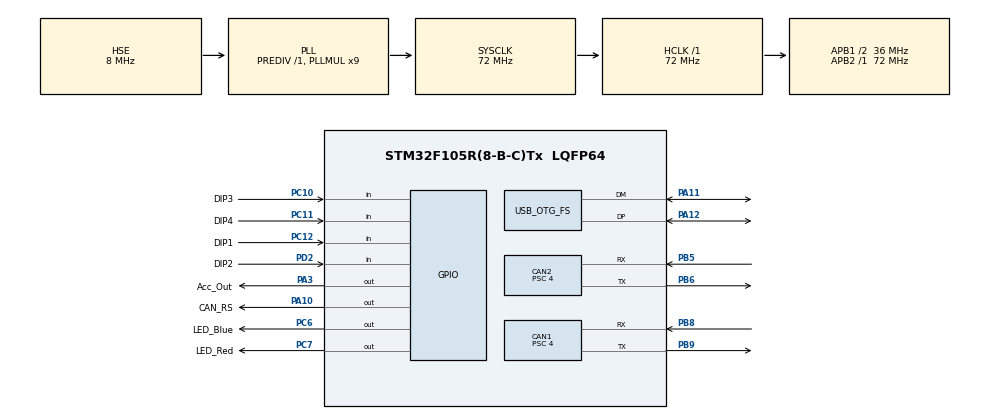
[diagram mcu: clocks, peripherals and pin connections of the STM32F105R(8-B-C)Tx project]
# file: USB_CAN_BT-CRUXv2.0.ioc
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CAN1.ABOM=ENABLE
CAN1.AWUM=ENABLE
CAN1.BS1=CAN_BS1_15TQ
CAN1.BS2=CAN_BS2_2TQ
CAN1.CalculateTimeBit=2000
CAN1.CalculateTimeQuantum=111.11111111111111
CAN1.NART=ENABLE
CAN1.Prescaler=4
CAN1.TXFP=ENABLE
CAN2.ABOM=ENABLE
CAN2.AWUM=ENABLE
CAN2.BS1=CAN_BS1_15TQ
CAN2.BS2=CAN_BS2_2TQ
CAN2.CalculateTimeBit=2000
CAN2.CalculateTimeQuantum=111.11111111111111
CAN2.NART=ENABLE
CAN2.Prescaler=4
CAN2.TXFP=ENABLE
Mcu.Family=STM32F1
Mcu.Name=STM32F105R(8-B-C)Tx
Mcu.Package=LQFP64
NVIC.CAN1_RX0_IRQn=true\:3\:0\:true\:false\:true\:true\:true
NVIC.CAN2_RX0_IRQn=true\:3\:0\:true\:false\:true\:true\:true
NVIC.OTG_FS_IRQn=true\:7\:0\:true\:false\:true\:false\:true
NVIC.PriorityGroup=NVIC_PRIORITYGROUP_4
PA10.GPIO_Label=CAN_RS
PA10.Signal=GPIO_Output
PA11.Mode=Device_Only
PA11.Signal=USB_OTG_FS_DM
PA12.Mode=Device_Only
PA12.Signal=USB_OTG_FS_DP
PA13.Mode=Serial_Wire
PA13.Signal=SYS_JTMS-SWDIO
PA14.Mode=Serial_Wire
PA14.Signal=SYS_JTCK-SWCLK
PA3.GPIO_Label=Acc_Out
PA3.Signal=GPIO_Output
PB5.Mode=Slave
PB5.Signal=CAN2_RX
PB6.Mode=Slave
PB6.Signal=CAN2_TX
PB8.GPIO_PuPd=GPIO_NOPULL
PB8.Mode=Master
PB8.Signal=CAN1_RX
PB9.Mode=Master
PB9.Signal=CAN1_TX
PC10.GPIO_Label=DIP3
PC10.Signal=GPIO_Input
PC11.GPIO_Label=DIP4
PC11.Signal=GPIO_Input
PC12.GPIO_Label=DIP1
PC12.Signal=GPIO_Input
PC6.GPIO_Label=LED_Blue
PC6.Signal=GPIO_Output
PC7.GPIO_Label=LED_Red
PC7.Signal=GPIO_Output
PD0-OSC_IN.Mode=HSE-External-Oscillator
PD0-OSC_IN.Signal=RCC_OSC_IN
PD1-OSC_OUT.Mode=HSE-External-Oscillator
PD1-OSC_OUT.Signal=RCC_OSC_OUT
PD2.GPIO_Label=DIP2
PD2.Signal=GPIO_Input
ProjectManager.HeapSize=0x600
ProjectManager.StackSize=0x400
ProjectManager.TargetToolchain=STM32CubeIDE
RCC.AHBFreq_Value=72000000
RCC.APB1CLKDivider=RCC_HCLK_DIV2
RCC.APB1Freq_Value=36000000
RCC.APB1TimFreq_Value=72000000
RCC.APB2Freq_Value=72000000
RCC.APB2TimFreq_Value=72000000
RCC.HCLKFreq_Value=72000000
RCC.PLLMUL=RCC_PLL_MUL9
RCC.PeriphClockSelection=RCC_PERIPHCLK_RTCVar|RCC_PERIPHCLK_ADCVar|RCC_PERIPHCLK_I2S2Var|RCC_PERIPHCLK_I2S3Var|RCC_PERIPHCLK_USB
RCC.SYSCLKFreq_VALUE=72000000
RCC.SYSCLKSource=RCC_SYSCLKSOURCE_PLLCLK
RCC.USBFreq_Value=48000000
USB_DEVICE.CLASS_NAME_FS=CUSTOM_HID
USB_DEVICE.USBD_CUSTOMHID_OUTREPORT_BUF_SIZE=17
USB_DEVICE.USBD_CUSTOM_HID_REPORT_DESC_SIZE=33
USB_DEVICE.VirtualMode=CustomHid
USB_DEVICE.VirtualModeFS=Custom_Hid_FS
USB_OTG_FS.VirtualMode=Device_Only
VP_USB_DEVICE_VS_USB_DEVICE_CUSTOM_HID_FS.Mode=CUSTOM_HID_FS
board=custom

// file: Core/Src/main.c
/* USER CODE BEGIN Header */
/**
  ******************************************************************************
  * @file           : main.c
  * @brief          : Main program body
  ******************************************************************************
  * @attention
  *
  * <h2><center>&copy; Copyright (c) 2019 STMicroelectronics.
  * All rights reserved.</center></h2>
  *
  * This software component is licensed by ST under BSD 3-Clause license,
  * the "License"; You may not use this file except in compliance with the
  * License. You may obtain a copy of the License at:
  *                        opensource.org/licenses/BSD-3-Clause
  *
  ******************************************************************************
  */
/* USER CODE END Header */

#include "main.h"
#include "usb_device.h"

/* USER CODE BEGIN Includes */
#include "PollingRoutines.h"
#include "CAN_Filter.h"
/* USER CODE END Includes */

CAN_HandleTypeDef hcan1;
CAN_HandleTypeDef hcan2;

void SystemClock_Config(void);
static void MX_GPIO_Init(void);
static void MX_CAN1_Init(void);
static void MX_CAN2_Init(void);

int main(void)
{

  /* MCU Configuration--------------------------------------------------------*/

  /* Reset of all peripherals, Initializes the Flash interface and the Systick. */
  HAL_Init();

  /* Configure the system clock */
  SystemClock_Config();

  /* Initialize all configured peripherals */
  MX_GPIO_Init();
  MX_CAN1_Init();
  MX_CAN2_Init();
  MX_USB_DEVICE_Init();
  /* USER CODE BEGIN 2 */
  SetCanFilter();
  /* USER CODE END 2 */

  /* Infinite loop */
  /* USER CODE BEGIN WHILE */
  while (1)
  {
	  PollingRoutine();
    /* USER CODE END WHILE */

  }
}

void SystemClock_Config(void)
{
  RCC_OscInitTypeDef RCC_OscInitStruct = {0};
  RCC_ClkInitTypeDef RCC_ClkInitStruct = {0};
  RCC_PeriphCLKInitTypeDef PeriphClkInit = {0};

  /** Initializes the CPU, AHB and APB busses clocks
  */
  RCC_OscInitStruct.OscillatorType = RCC_OSCILLATORTYPE_HSE;
  RCC_OscInitStruct.HSEState = RCC_HSE_ON;
  RCC_OscInitStruct.HSEPredivValue = RCC_HSE_PREDIV_DIV1;
  RCC_OscInitStruct.HSIState = RCC_HSI_ON;
  RCC_OscInitStruct.Prediv1Source = RCC_PREDIV1_SOURCE_HSE;
  RCC_OscInitStruct.PLL.PLLState = RCC_PLL_ON;
  RCC_OscInitStruct.PLL.PLLSource = RCC_PLLSOURCE_HSE;
  RCC_OscInitStruct.PLL.PLLMUL = RCC_PLL_MUL9;
  RCC_OscInitStruct.PLL2.PLL2State = RCC_PLL_NONE;
  if (HAL_RCC_OscConfig(&RCC_OscInitStruct) != HAL_OK)
  {
    Error_Handler();
  }
  /** Initializes the CPU, AHB and APB busses clocks
  */
  RCC_ClkInitStruct.ClockType = RCC_CLOCKTYPE_HCLK|RCC_CLOCKTYPE_SYSCLK
                              |RCC_CLOCKTYPE_PCLK1|RCC_CLOCKTYPE_PCLK2;
  RCC_ClkInitStruct.SYSCLKSource = RCC_SYSCLKSOURCE_PLLCLK;
  RCC_ClkInitStruct.AHBCLKDivider = RCC_SYSCLK_DIV1;
  RCC_ClkInitStruct.APB1CLKDivider = RCC_HCLK_DIV2;
  RCC_ClkInitStruct.APB2CLKDivider = RCC_HCLK_DIV1;

  if (HAL_RCC_ClockConfig(&RCC_ClkInitStruct, FLASH_LATENCY_2) != HAL_OK)
  {
    Error_Handler();
  }
  PeriphClkInit.PeriphClockSelection = RCC_PERIPHCLK_RTC|RCC_PERIPHCLK_ADC
                              |RCC_PERIPHCLK_I2S2|RCC_PERIPHCLK_I2S3
                              |RCC_PERIPHCLK_USB;
  PeriphClkInit.UsbClockSelection = RCC_USBCLKSOURCE_PLL_DIV3;
  if (HAL_RCCEx_PeriphCLKConfig(&PeriphClkInit) != HAL_OK)
  {
    Error_Handler();
  }
  /** Configure the Systick interrupt time
  */
  __HAL_RCC_PLLI2S_ENABLE();
}

static void MX_CAN1_Init(void)
{

  hcan1.Instance = CAN1;
  hcan1.Init.Prescaler = 4;
  hcan1.Init.Mode = CAN_MODE_NORMAL;
  hcan1.Init.SyncJumpWidth = CAN_SJW_1TQ;
  hcan1.Init.TimeSeg1 = CAN_BS1_15TQ;
  hcan1.Init.TimeSeg2 = CAN_BS2_2TQ;
  hcan1.Init.TimeTriggeredMode = DISABLE;
  hcan1.Init.AutoBusOff = ENABLE;
  hcan1.Init.AutoWakeUp = ENABLE;
  hcan1.Init.AutoRetransmission = ENABLE;
  hcan1.Init.ReceiveFifoLocked = DISABLE;
  hcan1.Init.TransmitFifoPriority = ENABLE;
  if (HAL_CAN_Init(&hcan1) != HAL_OK)
  {
    Error_Handler();
  }

}

static void MX_CAN2_Init(void)
{

  hcan2.Instance = CAN2;
  hcan2.Init.Prescaler = 4;
  hcan2.Init.Mode = CAN_MODE_NORMAL;
  hcan2.Init.SyncJumpWidth = CAN_SJW_1TQ;
  hcan2.Init.TimeSeg1 = CAN_BS1_15TQ;
  hcan2.Init.TimeSeg2 = CAN_BS2_2TQ;
  hcan2.Init.TimeTriggeredMode = DISABLE;
  hcan2.Init.AutoBusOff = ENABLE;
  hcan2.Init.AutoWakeUp = ENABLE;
  hcan2.Init.AutoRetransmission = ENABLE;
  hcan2.Init.ReceiveFifoLocked = DISABLE;
  hcan2.Init.TransmitFifoPriority = ENABLE;
  if (HAL_CAN_Init(&hcan2) != HAL_OK)
  {
    Error_Handler();
  }

}

static void MX_GPIO_Init(void)
{
  GPIO_InitTypeDef GPIO_InitStruct = {0};

  /* GPIO Ports Clock Enable */
  __HAL_RCC_GPIOD_CLK_ENABLE();
  __HAL_RCC_GPIOA_CLK_ENABLE();
  __HAL_RCC_GPIOC_CLK_ENABLE();
  __HAL_RCC_GPIOB_CLK_ENABLE();

  /*Configure GPIO pin Output Level */
  HAL_GPIO_WritePin(GPIOA, Acc_Out_Pin|CAN_RS_Pin, GPIO_PIN_RESET);

  /*Configure GPIO pin Output Level */
  HAL_GPIO_WritePin(GPIOC, LED_Blue_Pin|LED_Red_Pin, GPIO_PIN_RESET);

  /*Configure GPIO pins : Acc_Out_Pin CAN_RS_Pin */
  GPIO_InitStruct.Pin = Acc_Out_Pin|CAN_RS_Pin;
  GPIO_InitStruct.Mode = GPIO_MODE_OUTPUT_PP;
  GPIO_InitStruct.Pull = GPIO_NOPULL;
  GPIO_InitStruct.Speed = GPIO_SPEED_FREQ_LOW;
  HAL_GPIO_Init(GPIOA, &GPIO_InitStruct);

  /*Configure GPIO pins : LED_Blue_Pin LED_Red_Pin */
  GPIO_InitStruct.Pin = LED_Blue_Pin|LED_Red_Pin;
  GPIO_InitStruct.Mode = GPIO_MODE_OUTPUT_PP;
  GPIO_InitStruct.Pull = GPIO_NOPULL;
  GPIO_InitStruct.Speed = GPIO_SPEED_FREQ_LOW;
  HAL_GPIO_Init(GPIOC, &GPIO_InitStruct);

  /*Configure GPIO pins : DIP3_Pin DIP4_Pin DIP1_Pin */
  GPIO_InitStruct.Pin = DIP3_Pin|DIP4_Pin|DIP1_Pin;
  GPIO_InitStruct.Mode = GPIO_MODE_INPUT;
  GPIO_InitStruct.Pull = GPIO_NOPULL;
  HAL_GPIO_Init(GPIOC, &GPIO_InitStruct);

  /*Configure GPIO pin : DIP2_Pin */
  GPIO_InitStruct.Pin = DIP2_Pin;
  GPIO_InitStruct.Mode = GPIO_MODE_INPUT;
  GPIO_InitStruct.Pull = GPIO_NOPULL;
  HAL_GPIO_Init(DIP2_GPIO_Port, &GPIO_InitStruct);

}

void Error_Handler(void)
{
}

/************************ (C) COPYRIGHT STMicroelectronics *****END OF FILE****/
